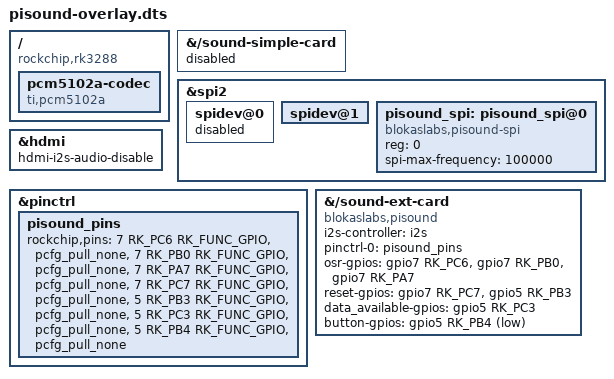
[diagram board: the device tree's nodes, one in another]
/*
 * Pisound Linux kernel module.
 * Copyright (C) 2016-2019  Vilniaus Blokas UAB, https://blokas.io/pisound
 *
 * This program is free software; you can redistribute it and/or
 * modify it under the terms of the GNU General Public License
 * as published by the Free Software Foundation; version 2 of the
 * License.
 *
 * This program is distributed in the hope that it will be useful,
 * but WITHOUT ANY WARRANTY; without even the implied warranty of
 * MERCHANTABILITY or FITNESS FOR A PARTICULAR PURPOSE.  See the
 * GNU General Public License for more details.
 *
 * You should have received a copy of the GNU General Public License
 * along with this program; if not, write to the Free Software
 * Foundation, Inc., 51 Franklin Street, Fifth Floor, Boston, MA  02110-1301, USA.
 */

/dts-v1/;
/plugin/;

#include <dt-bindings/gpio/gpio.h>
#include <dt-bindings/pinctrl/rockchip.h>

/ {
	compatible = "rockchip,rk3288";

	fragment@0 {
		target-path = "/sound-simple-card";
		__overlay__ {
			status = "disabled";
		};
	};

	fragment@1 {
		target = <&spi2>;
		__overlay__ {
			#address-cells = <1>;
			#size-cells = <0>;
			status = "okay";
			spidev@0 {
				status="disabled";
			};
			spidev@1 {
				status="okay";
			};
			pisound_spi: pisound_spi@0{
				compatible = "blokaslabs,pisound-spi";
				reg = <0>;
				spi-max-frequency = <100000>;
			};
		};
	};
	
	fragment@2 {
		target = <&hdmi>;
		__overlay__ {
			hdmi-i2s-audio-disable;
		};
	};

	fragment@3 {
		target-path = "/";
		__overlay__ {
			pcm5102a-codec {
				#sound-dai-cells = <0>;
				compatible = "ti,pcm5102a";
				status = "okay";
			};
		};
	};

	fragment@4 {
		target = <&pinctrl>;
		__overlay__ {
			pisound_pins: pisound_pins {
				rockchip,pins =
					<7 RK_PC6 RK_FUNC_GPIO &pcfg_pull_none>,
					<7 RK_PB0 RK_FUNC_GPIO &pcfg_pull_none>,
					<7 RK_PA7 RK_FUNC_GPIO &pcfg_pull_none>,
					<7 RK_PC7 RK_FUNC_GPIO &pcfg_pull_none>,
					<5 RK_PB3 RK_FUNC_GPIO &pcfg_pull_none>,
					<5 RK_PC3 RK_FUNC_GPIO &pcfg_pull_none>,
					<5 RK_PB4 RK_FUNC_GPIO &pcfg_pull_none>;
			};
		};
	};

	fragment@5 {
		target-path = "/sound-ext-card";
		__overlay__ {
			compatible = "blokaslabs,pisound";
			i2s-controller = <&i2s>;
			status = "okay";

			pinctrl-names = "default";
			pinctrl-0 = <&pisound_pins>;

			osr-gpios =
				<&gpio7 RK_PC6 GPIO_ACTIVE_HIGH>, // GP7C6
				<&gpio7 RK_PB0 GPIO_ACTIVE_HIGH>, // GP7B0
				<&gpio7 RK_PA7 GPIO_ACTIVE_HIGH>; // GP7A7

			reset-gpios =
				<&gpio7 RK_PC7 GPIO_ACTIVE_HIGH>, // GP7C7
				<&gpio5 RK_PB3 GPIO_ACTIVE_HIGH>; // GP5B3

			data_available-gpios = <&gpio5 RK_PC3 GPIO_ACTIVE_HIGH>; // GP5C3

			button-gpios = <&gpio5 RK_PB4 GPIO_ACTIVE_LOW>; // GP5B4
		};
	};
};
